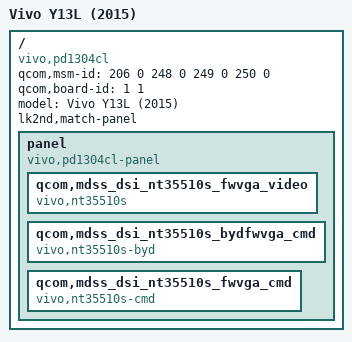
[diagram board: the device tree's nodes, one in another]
// SPDX-License-Identifier: BSD-3-Clause

/dts-v1/;

#include <skeleton.dtsi>

/ {
	qcom,msm-id = <206 0 248 0 249 0 250 0>;
    qcom,board-id = <1 1>;

	model = "Vivo Y13L (2015)";
	compatible = "vivo,pd1304cl", "qcom,msm8916", "lk2nd,device";
	lk2nd,match-panel;

	panel {
		compatible = "vivo,pd1304cl-panel";

		qcom,mdss_dsi_nt35510s_fwvga_video{
			compatible = "vivo,nt35510s";
		};
		qcom,mdss_dsi_nt35510s_bydfwvga_cmd {
			compatible = "vivo,nt35510s-byd";
		};
		qcom,mdss_dsi_nt35510s_fwvga_cmd {
			compatible = "vivo,nt35510s-cmd";
		};
	};
};
